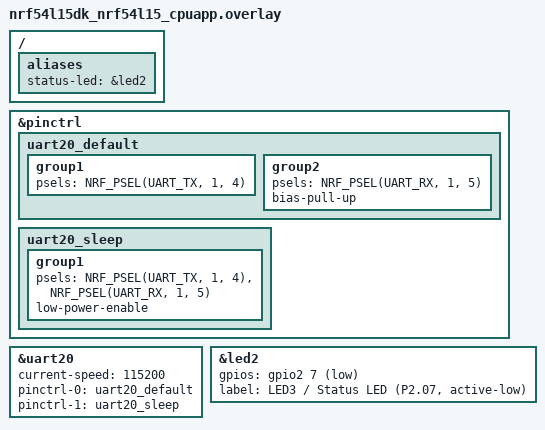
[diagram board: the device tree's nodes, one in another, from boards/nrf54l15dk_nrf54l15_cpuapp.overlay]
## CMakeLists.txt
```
#
# Copyright (c) 2018 Nordic Semiconductor
#
# SPDX-License-Identifier: LicenseRef-Nordic-5-Clause
#
cmake_minimum_required(VERSION 3.20.0)

find_package(Zephyr REQUIRED HINTS $ENV{ZEPHYR_BASE})
project(esb_ptx)

target_include_directories(app PRIVATE ../common)

# Pairing addresses are owned by xbox_central; PTX is runtime-only.
target_compile_definitions(app PRIVATE
  ESB_RADIO_SUBTREE=\"esb_ptx\"
  ESB_RADIO_MODE=ESB_MODE_PTX
  RC_ESB_RADIO_PERSIST=0
)

target_sources(app PRIVATE
  src/main.c
  src/rc_ptx_uart_channels.c
  src/rc_ptx_status_led.c
  src/rc_uart_bridge.c
  ../common/rc_link.c
  ../common/rc_channel_bank.c
  ../common/uart_rc_link.c
  ../common/rc_esb_radio.c
  ../common/rc_uart_esb_req_work.c
  ../common/rc_uart_log_fwd.c
)
```

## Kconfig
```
#
# Copyright (c) 2020 Nordic Semiconductor
#
# SPDX-License-Identifier: LicenseRef-Nordic-5-Clause
#

source "Kconfig.zephyr"

menu "Enhanced ShockBurst: Transmitter"

config ESB_PTX_APP_LOG_LEVEL
	int "Log level for the ESB PTX sample"
	default 2

endmenu
```

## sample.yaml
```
sample:
  name: ESB ptx
tests:
  sample.esb.ptx.build:
    sysbuild: true
    build_only: true
    integration_platforms:
      - nrf54l15dk/nrf54l15/cpuapp
    platform_allow:
      - nrf54l15dk/nrf54l15/cpuapp
    tags:
      - esb
      - ci_build
      - sysbuild
```

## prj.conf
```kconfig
#
# Copyright (c) 2019 Nordic Semiconductor ASA
#
# SPDX-License-Identifier: LicenseRef-Nordic-5-Clause
#
CONFIG_NCS_SAMPLES_DEFAULTS=y
CONFIG_ESB=y
CONFIG_DK_LIBRARY=y
CONFIG_CLOCK_CONTROL=y

# Required for ESB on nRF54L15 (DPPIC instance 10).
CONFIG_NRFX_DPPI10=y

# Console UART is shared with the Hub RC link (HUART-RC protocol).
CONFIG_UART_INTERRUPT_DRIVEN=y
CONFIG_SETTINGS=y
CONFIG_ZMS=y
CONFIG_SETTINGS_ZMS=y
CONFIG_PM_PARTITION_SIZE_SETTINGS_STORAGE=0x2000
CONFIG_FLASH=y
CONFIG_FLASH_MAP=y
CONFIG_ENTROPY_GENERATOR=y
CONFIG_GPIO=y

# Required by rc_uart_log_fwd custom log backend.
CONFIG_LOG_MODE_DEFERRED=y
CONFIG_LOG_OUTPUT=y

# Quiet default: WRN+ only. UART20 is shared with Hub HUART-RC link.
CONFIG_ESB_PTX_APP_LOG_LEVEL=2
CONFIG_LOG_DEFAULT_LEVEL=2
```

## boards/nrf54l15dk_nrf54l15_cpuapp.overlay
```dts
/*
 * SPDX-License-Identifier: LicenseRef-Nordic-5-Clause
 *
 * Console / Hub RC link on uart20: TX/RX only (no hardware flow control).
 * Match Ground BLE Hub uart30 speed for the wired RC link.
 *
 * Status LED on P2.07 (DK LED3 / led2): lost 1 Hz, PRX link solid, pair rapid.
 */

#include <zephyr/dt-bindings/gpio/gpio.h>

&pinctrl {
	uart20_default: uart20_default {
		group1 {
			psels = <NRF_PSEL(UART_TX, 1, 4)>;
		};

		group2 {
			psels = <NRF_PSEL(UART_RX, 1, 5)>;
			bias-pull-up;
		};
	};

	uart20_sleep: uart20_sleep {
		group1 {
			psels = <NRF_PSEL(UART_TX, 1, 4)>,
				<NRF_PSEL(UART_RX, 1, 5)>;
			low-power-enable;
		};
	};
};

&uart20 {
	current-speed = <115200>;
	pinctrl-0 = <&uart20_default>;
	pinctrl-1 = <&uart20_sleep>;
	pinctrl-names = "default", "sleep";
};

/*
 * Override DK LED3 (DT: led2, P2.07): external status LED is active-low.
 */
&led2 {
	gpios = <&gpio2 7 GPIO_ACTIVE_LOW>;
	label = "LED3 / Status LED (P2.07, active-low)";
};

/ {
	aliases {
		status-led = &led2;
	};
};
```

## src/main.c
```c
/*
 * Copyright (c) 2018 Nordic Semiconductor ASA
 *
 * SPDX-License-Identifier: LicenseRef-Nordic-5-Clause
 */
#include <zephyr/drivers/clock_control.h>
#include <zephyr/drivers/clock_control/nrf_clock_control.h>
#include <zephyr/drivers/gpio.h>
#include <zephyr/irq.h>
#include <zephyr/logging/log.h>
#include <nrf.h>
#include <esb.h>
#include <zephyr/device.h>
#include <zephyr/devicetree.h>
#include <zephyr/kernel.h>
#include <zephyr/types.h>
#include <dk_buttons_and_leds.h>
#if defined(CONFIG_CLOCK_CONTROL_NRF2)
#include <hal/nrf_lrcconf.h>
#endif
#include <nrf_erratas.h>
#if NRF54L_ERRATA_20_PRESENT
#include <hal/nrf_power.h>
#endif /* NRF54L_ERRATA_20_PRESENT */
#if defined(NRF54LM20A_ENGA_XXAA)
#include <hal/nrf_clock.h>
#endif /* defined(NRF54LM20A_ENGA_XXAA) */

#include "rc_channel_bank.h"
#include "rc_esb_radio.h"
#include "rc_link.h"
#include "rc_ptx_status_led.h"
#include "rc_ptx_uart_channels.h"
#include "rc_uart_bridge.h"

LOG_MODULE_REGISTER(esb_ptx, CONFIG_ESB_PTX_APP_LOG_LEVEL);

#define TX_INTERVAL_MS 100
#define PAIR_TX_INTERVAL_MS 1000

static bool ready = true;
static uint8_t ctrl_seq;
static uint8_t pair_seq;
static uint8_t peer_status_channels;
static struct esb_payload rx_payload;
static struct esb_payload tx_payload;
static struct rc_link_frame ctrl_frame;
static int64_t next_pair_tx_ms;
static bool pending_pair_restore;
static bool pair_probe_pending;
static bool pair_led_latched;
static struct uart_rc_esb_config saved_paired_cfg;

static void pair_complete(const char *reason)
{
	pending_pair_restore = false;
	pair_probe_pending = false;
	(void)rc_esb_radio_apply_cfg(&saved_paired_cfg);
	rc_esb_radio_end_pair_broadcast();
	if (pair_led_latched) {
		pair_led_latched = false;
		rc_ptx_status_led_set_pairing(false);
	}
	LOG_WRN("%s — enter UART CTRL forward", reason);
}

static void restore_paired_radio_cfg(void)
{
	if (!pending_pair_restore) {
		return;
	}

	(void)rc_esb_radio_apply_cfg(&saved_paired_cfg);
	pending_pair_restore = false;
}

static void handle_status_frame(const struct esb_payload *payload)
{
	struct rc_link_frame status;
	int err;

	err = rc_link_unpack(payload->data, payload->length, &status);
	if (err || status.type != RC_LINK_TYPE_STATUS) {
		LOG_DBG("Ignore invalid status frame: %d", err);
		return;
	}

	if (peer_status_channels != status.channel_count) {
		peer_status_channels = status.channel_count;
		LOG_DBG("Aircraft status channel count: %u", peer_status_channels);
	}

	rc_uart_bridge_on_esb_status(&status);
}

void event_handler(struct esb_evt const *event)
{
	static uint16_t pair_tx_ok;
	static uint16_t pair_tx_fail;

	ready = true;

	switch (event->evt_id) {
	case ESB_EVENT_TX_SUCCESS:
		if (rc_esb_radio_pair_broadcast_active()) {
			if (pending_pair_restore) {
				/* ACK on default listen address. */
				pair_tx_ok++;
				restore_paired_radio_cfg();
				pair_complete("PRX ACK on PAIR");
				LOG_WRN("pair stats ok=%u fail=%u", pair_tx_ok, pair_tx_fail);
				pair_tx_ok = 0;
				pair_tx_fail = 0;
			} else if (pair_probe_pending) {
				/*
				 * ACK on the new paired address — PRX already
				 * applied even if the default-addr ACK was lost.
				 */
				pair_probe_pending = false;
				pair_complete("PRX reachable on new addr");
				pair_tx_ok = 0;
				pair_tx_fail = 0;
			} else {
				restore_paired_radio_cfg();
			}
		} else {
			restore_paired_radio_cfg();
			/* PRX ACKed CTRL — RF link alive. */
			rc_ptx_status_led_on_link();
			LOG_DBG("Control frame sent");
		}
		break;
	case ESB_EVENT_TX_FAILED:
		if (pending_pair_restore && rc_esb_radio_pair_broadcast_active()) {
			pair_tx_fail++;
			LOG_WRN("PAIR TX no ACK (fail=%u) — probe new addr next",
				pair_tx_fail);
			restore_paired_radio_cfg();
			/* PRX may already have paired; probe on new addresses. */
			pair_probe_pending = true;
			pending_pair_restore = false;
		} else if (pair_probe_pending && rc_esb_radio_pair_broadcast_active()) {
			LOG_WRN("New-addr probe no ACK — resume PAIR broadcast");
			pair_probe_pending = false;
		} else {
			restore_paired_radio_cfg();
			LOG_DBG("Control/PAIR frame failed");
		}
		break;
	case ESB_EVENT_RX_RECEIVED:
		while (esb_read_rx_payload(&rx_payload) == 0) {
			handle_status_frame(&rx_payload);
		}
		/*
		 * STATUS on the new address during pair window also proves PRX
		 * applied the paired config.
		 */
		if (rc_esb_radio_pair_broadcast_active() && !pending_pair_restore) {
			pair_probe_pending = false;
			pair_complete("STATUS RX on new addr");
		}
		break;
	default:
		break;
	}
}

#if defined(CONFIG_CLOCK_CONTROL_NRF)
int clocks_start(void)
{
	int err;
	int res;
	struct onoff_manager *clk_mgr;
	struct onoff_client clk_cli;

	clk_mgr = z_nrf_clock_control_get_onoff(CLOCK_CONTROL_NRF_SUBSYS_HF);
	if (!clk_mgr) {
		LOG_ERR("Unable to get the Clock manager");
		return -ENXIO;
	}

	sys_notify_init_spinwait(&clk_cli.notify);

	err = onoff_request(clk_mgr, &clk_cli);
	if (err < 0) {
		LOG_ERR("Clock request failed: %d", err);
		return err;
	}

	do {
		err = sys_notify_fetch_result(&clk_cli.notify, &res);
		if (!err && res) {
			LOG_ERR("Clock could not be started: %d", res);
			return res;
		}
	} while (err);

#if NRF54L_ERRATA_20_PRESENT
	if (nrf54l_errata_20()) {
		nrf_power_task_trigger(NRF_POWER, NRF_POWER_TASK_CONSTLAT);
	}
#endif /* NRF54L_ERRATA_20_PRESENT */

#if defined(NRF54LM20A_ENGA_XXAA)
	nrf_clock_task_trigger(NRF_CLOCK, NRF_CLOCK_TASK_PLLSTART);
#endif

	LOG_DBG("HF clock started");
	return 0;
}

#elif defined(CONFIG_CLOCK_CONTROL_NRF2)

int clocks_start(void)
{
	int err;
	int res;
	const struct device *radio_clk_dev =
		DEVICE_DT_GET_OR_NULL(DT_CLOCKS_CTLR(DT_NODELABEL(radio)));
	struct onoff_client radio_cli;

	nrf_lrcconf_poweron_force_set(NRF_LRCCONF010, NRF_LRCCONF_POWER_DOMAIN_1, true);

	sys_notify_init_spinwait(&radio_cli.notify);

	err = nrf_clock_control_request(radio_clk_dev, NULL, &radio_cli);

	do {
		err = sys_notify_fetch_result(&radio_cli.notify, &res);
		if (!err && res) {
			LOG_ERR("Clock could not be started: %d", res);
			return res;
		}
	} while (err == -EAGAIN);

	nrf_lrcconf_clock_always_run_force_set(NRF_LRCCONF000, 0, true);
	nrf_lrcconf_task_trigger(NRF_LRCCONF000, NRF_LRCCONF_TASK_CLKSTART_0);

	LOG_DBG("HF clock started");
	return 0;
}

#else
BUILD_ASSERT(false, "No Clock Control driver");
#endif /* defined(CONFIG_CLOCK_CONTROL_NRF2) */

int esb_initialize(void)
{
	return rc_esb_radio_init(event_handler);
}

static int pack_ctrl_payload(struct esb_payload *payload)
{
	int len;

	len = rc_link_pack(&ctrl_frame, payload->data, sizeof(payload->data));
	if (len < 0) {
		return len;
	}

	payload->length = (uint8_t)len;
	payload->pipe = RC_LINK_PIPE;
	payload->noack = false;

	return 0;
}

static int pack_pair_payload(struct esb_payload *payload)
{
	struct rc_link_pair_payload pair_payload;
	struct rc_link_frame pair_frame;
	int err;
	int len;

	err = rc_esb_radio_export_pair_payload(&pair_payload);
	if (err != 0) {
		return err;
	}

	err = rc_link_pair_encode(&pair_payload, pair_seq++, &pair_frame);
	if (err != 0) {
		return err;
	}

	len = rc_link_pack(&pair_frame, payload->data, sizeof(payload->data));
	if (len < 0) {
		return len;
	}

	payload->length = (uint8_t)len;
	payload->pipe = RC_LINK_PIPE;
	payload->noack = false;

	return 0;
}

int main(void)
{
	int err;

	LOG_WRN("ESB PTX ready (UART RC; Hub owns pair store; Btn1 PAIR until PRX ACK)");

	err = clocks_start();
	if (err) {
		return 0;
	}

	err = dk_leds_init();
	if (err) {
		LOG_ERR("LEDs initialization failed, err %d", err);
		return 0;
	}

	err = rc_ptx_status_led_init();
	if (err) {
		LOG_WRN("status LED init failed: %d", err);
	}

	err = esb_initialize();
	if (err) {
		LOG_ERR("ESB initialization failed, err %d", err);
		return 0;
	}

	LOG_WRN("No local pair store — wait Hub SET_ADDR/APPLY (boot) or Btn1 PAIR");

	err = rc_uart_bridge_init();
	if (err) {
		LOG_ERR("UART RC bridge init failed, err %d", err);
		return 0;
	}

	next_pair_tx_ms = 0;

	while (1) {
		if (ready) {
			ready = false;
			esb_flush_tx();

			struct uart_rc_esb_config paired_cfg;
			const bool pair_window = rc_esb_radio_pair_broadcast_active();

			if (pair_window && !pair_led_latched) {
				pair_led_latched = true;
				rc_ptx_status_led_set_pairing(true);
			} else if (!pair_window && pair_led_latched) {
				pair_led_latched = false;
				rc_ptx_status_led_set_pairing(false);
			}

			if (pair_window && pair_probe_pending) {
				/*
				 * After a lost default-addr ACK, PRX may already be on
				 * the new addresses. Probe there before more PAIR TX.
				 */
				(void)rc_esb_radio_get_config(&paired_cfg);
				saved_paired_cfg = paired_cfg;
				err = pack_pair_payload(&tx_payload);
				if (err) {
					LOG_ERR("Pack probe frame failed: %d", err);
					pair_probe_pending = false;
					ready = true;
					continue;
				}
				pending_pair_restore = false;
				LOG_WRN("Probe TX on new paired addr (len=%u)", tx_payload.length);
			} else if (pair_window && k_uptime_get() >= next_pair_tx_ms) {
				next_pair_tx_ms = k_uptime_get() + PAIR_TX_INTERVAL_MS;

				(void)rc_esb_radio_get_config(&paired_cfg);
				err = pack_pair_payload(&tx_payload);
				if (err) {
					LOG_ERR("Pack pair frame failed: %d", err);
					ready = true;
					continue;
				}

				err = rc_esb_radio_apply_pair_listen();
				if (err != 0) {
					LOG_ERR("Apply pair listen failed: %d", err);
					ready = true;
					continue;
				}
				saved_paired_cfg = paired_cfg;
				pending_pair_restore = true;
				pair_probe_pending = false;
				LOG_WRN("PAIR TX on default addr (seq payload len=%u)",
					tx_payload.length);
			} else if (!pair_window) {
				const struct rc_channel_bank *bank =
					rc_ptx_get_active_control_bank();

				if (bank == NULL) {
					ready = true;
					continue;
				}

				err = rc_link_frame_fill(&ctrl_frame, RC_LINK_TYPE_CTRL, ctrl_seq++, 0,
							 bank);
				if (err) {
					LOG_ERR("Prepare control frame failed: %d", err);
					ready = true;
					continue;
				}

				err = pack_ctrl_payload(&tx_payload);
			} else {
				/* Pair window active but waiting for next PAIR slot. */
				ready = true;
				continue;
			}
			if (err) {
				LOG_ERR("Pack TX frame failed: %d", err);
				ready = true;
				continue;
			}

			err = esb_write_payload(&tx_payload);
			if (err) {
				LOG_ERR("Payload write failed, err %d", err);
				restore_paired_radio_cfg();
				ready = true;
			}
		}
		k_sleep(K_MSEC(TX_INTERVAL_MS));
	}
}
```

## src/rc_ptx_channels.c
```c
/*
 * Copyright (c) 2026
 *
 * SPDX-License-Identifier: LicenseRef-Nordic-5-Clause
 */

#include "rc_ptx_channels.h"

#include <zephyr/sys/util.h>

static uint8_t *ctrl_seq_ref;

struct ptx_base_ctx {
	uint16_t base;
};

static int read_scaled_base(void *ctx, uint16_t *value)
{
	const struct ptx_base_ctx *cfg = ctx;

	*value = (uint16_t)(cfg->base + (ctrl_seq_ref ? (*ctrl_seq_ref % 100U) : 0U));
	return 0;
}

static int read_fixed(void *ctx, uint16_t *value)
{
	*value = (uint16_t)(uintptr_t)ctx;
	return 0;
}

static struct ptx_base_ctx aileron_cfg = {
	.base = 1500,
};

static const struct rc_channel_slot ptx_slots[] = {
	{ read_fixed, NULL, (void *)(uintptr_t)1000 },
	{ read_scaled_base, NULL, &aileron_cfg },
	{ read_fixed, NULL, (void *)(uintptr_t)1500 },
	{ read_fixed, NULL, (void *)(uintptr_t)1500 },
	{ read_fixed, NULL, (void *)(uintptr_t)1800 },
	{ read_fixed, NULL, (void *)(uintptr_t)1200 },
};

const struct rc_channel_bank rc_ptx_control_bank = {
	.slots = ptx_slots,
	.slot_count = ARRAY_SIZE(ptx_slots),
};

void rc_ptx_channels_bind_seq(uint8_t *seq)
{
	ctrl_seq_ref = seq;
}
```

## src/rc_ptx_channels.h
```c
/*
 * Copyright (c) 2026
 *
 * SPDX-License-Identifier: LicenseRef-Nordic-5-Clause
 */

#ifndef RC_PTX_CHANNELS_H_
#define RC_PTX_CHANNELS_H_

#include <stdint.h>

#include "rc_channel_bank.h"

extern const struct rc_channel_bank rc_ptx_control_bank;

void rc_ptx_channels_bind_seq(uint8_t *seq);

#endif /* RC_PTX_CHANNELS_H_ */
```

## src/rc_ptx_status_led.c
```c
/*
 * SPDX-License-Identifier: LicenseRef-Nordic-5-Clause
 */

#include "rc_ptx_status_led.h"

#include <errno.h>

#include <zephyr/device.h>
#include <zephyr/devicetree.h>
#include <zephyr/drivers/gpio.h>
#include <zephyr/kernel.h>
#include <zephyr/logging/log.h>

LOG_MODULE_REGISTER(rc_ptx_status_led, CONFIG_ESB_PTX_APP_LOG_LEVEL);

#if DT_NODE_EXISTS(DT_ALIAS(status_led))
#define STATUS_LED_NODE DT_ALIAS(status_led)
static const struct gpio_dt_spec status_led = GPIO_DT_SPEC_GET(STATUS_LED_NODE, gpios);
#define STATUS_LED_AVAILABLE 1
#else
#define STATUS_LED_AVAILABLE 0
#endif

/* 500 ms on / 500 ms off → 1 Hz when link lost. */
#define LOST_PERIOD_MS       1000U
#define PAIRING_PERIOD_MS     160U /* 80 ms on / 80 ms off */
/*
 * After the last CTRL TX_SUCCESS (PRX ACK), wait this long then 1 Hz lost blink.
 * Must be > Hub CTRL / PTX TX interval (~100 ms).
 */
#define LINK_LOST_TIMEOUT_MS  500U

enum status_led_mode {
	STATUS_LED_LOST = 0, /* 1 Hz */
	STATUS_LED_LINK,     /* solid */
	STATUS_LED_PAIRING,  /* rapid */
};

static enum status_led_mode mode = STATUS_LED_LOST;
static bool led_on;
static bool pairing_active;
static struct k_work_delayable blink_work;
static struct k_work_delayable lost_work;

static uint32_t period_for_mode(enum status_led_mode m)
{
	switch (m) {
	case STATUS_LED_PAIRING:
		return PAIRING_PERIOD_MS;
	case STATUS_LED_LOST:
		return LOST_PERIOD_MS;
	case STATUS_LED_LINK:
	default:
		return 0U;
	}
}

static void led_apply(bool on)
{
#if STATUS_LED_AVAILABLE
	(void)gpio_pin_set_dt(&status_led, on ? 1 : 0);
#else
	ARG_UNUSED(on);
#endif
	led_on = on;
}

static void apply_mode(enum status_led_mode next)
{
	uint32_t period;

	mode = next;
	(void)k_work_cancel_delayable(&blink_work);

	period = period_for_mode(mode);
	if (period == 0U) {
		/* LINK: solid on. */
		led_apply(true);
		return;
	}

	led_apply(true);
	(void)k_work_reschedule(&blink_work, K_MSEC(period / 2U));
}

static void blink_work_handler(struct k_work *work)
{
	uint32_t period;

	ARG_UNUSED(work);

	period = period_for_mode(mode);
	if (period == 0U) {
		led_apply(true);
		return;
	}

	led_apply(!led_on);
	(void)k_work_reschedule(&blink_work, K_MSEC(period / 2U));
}

static void lost_work_handler(struct k_work *work)
{
	ARG_UNUSED(work);

	if (pairing_active) {
		return;
	}

	apply_mode(STATUS_LED_LOST);
}

int rc_ptx_status_led_init(void)
{
#if !STATUS_LED_AVAILABLE
	LOG_WRN("status-led alias missing — status LED disabled");
	return -ENOENT;
#else
	int err;

	if (!gpio_is_ready_dt(&status_led)) {
		LOG_ERR("status-led GPIO not ready");
		return -ENODEV;
	}

	err = gpio_pin_configure_dt(&status_led, GPIO_OUTPUT_INACTIVE);
	if (err) {
		LOG_ERR("status-led configure failed: %d", err);
		return err;
	}

	k_work_init_delayable(&blink_work, blink_work_handler);
	k_work_init_delayable(&lost_work, lost_work_handler);
	pairing_active = false;
	apply_mode(STATUS_LED_LOST);
	LOG_WRN("status LED P2.07 — lost 1 Hz / PRX link solid / pair rapid");
	return 0;
#endif
}

void rc_ptx_status_led_on_link(void)
{
#if !STATUS_LED_AVAILABLE
	return;
#else
	if (pairing_active) {
		return;
	}

	(void)k_work_reschedule(&lost_work, K_MSEC(LINK_LOST_TIMEOUT_MS));

	if (mode != STATUS_LED_LINK) {
		apply_mode(STATUS_LED_LINK);
	}
#endif
}

void rc_ptx_status_led_set_pairing(bool pairing)
{
#if !STATUS_LED_AVAILABLE
	ARG_UNUSED(pairing);
	return;
#else
	pairing_active = pairing;
	(void)k_work_cancel_delayable(&lost_work);

	if (pairing) {
		apply_mode(STATUS_LED_PAIRING);
		return;
	}

	apply_mode(STATUS_LED_LOST);
#endif
}
```

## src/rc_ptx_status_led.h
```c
/*
 * SPDX-License-Identifier: LicenseRef-Nordic-5-Clause
 *
 * Status LED on DT alias status-led (P2.07):
 *   lost     — 1 Hz blink (no ESB ACK from PRX)
 *   link     — solid on (CTRL TX ACKed by PRX)
 *   pairing  — rapid blink (OTA PAIR broadcast)
 */

#ifndef RC_PTX_STATUS_LED_H_
#define RC_PTX_STATUS_LED_H_

#include <stdbool.h>

int rc_ptx_status_led_init(void);

/** ISR-safe: PRX ACK'd CTRL — solid on; refresh lost timer. */
void rc_ptx_status_led_on_link(void);

/** OTA PAIR broadcast indication (highest priority over link/lost). */
void rc_ptx_status_led_set_pairing(bool pairing);

#endif /* RC_PTX_STATUS_LED_H_ */
```

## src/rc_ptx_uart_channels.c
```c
/*
 * Copyright (c) 2026
 *
 * SPDX-License-Identifier: LicenseRef-Nordic-5-Clause
 */

#include "rc_ptx_uart_channels.h"

#include <zephyr/kernel.h>
#include <zephyr/sys/util.h>

static uint16_t uart_channel_values[UART_RC_LINK_MAX_CHANNELS];
static size_t uart_channel_count;
static int64_t uart_last_update_ms;

static int read_uart_channel(void *ctx, uint16_t *value)
{
	uintptr_t index = (uintptr_t)ctx;

	if (index >= uart_channel_count) {
		return -ENOENT;
	}

	*value = uart_channel_values[index];
	return 0;
}

static bool uart_channel_slot_available(void *ctx)
{
	uintptr_t index = (uintptr_t)ctx;

	return rc_ptx_uart_channels_active() && index < uart_channel_count;
}

static struct rc_channel_slot uart_slots[UART_RC_LINK_MAX_CHANNELS];

static const struct rc_channel_bank uart_bank = {
	.slots = uart_slots,
	.slot_count = ARRAY_SIZE(uart_slots),
};

void rc_ptx_uart_channels_update(const struct uart_rc_link_ctrl *ctrl)
{
	if (ctrl == NULL || ctrl->channel_count == 0U ||
	    ctrl->channel_count > UART_RC_LINK_MAX_CHANNELS) {
		return;
	}

	uart_channel_count = ctrl->channel_count;

	for (uint8_t i = 0; i < ctrl->channel_count; i++) {
		uart_channel_values[i] = ctrl->channels[i];
	}

	uart_last_update_ms = k_uptime_get();
}

bool rc_ptx_uart_channels_active(void)
{
	if (uart_channel_count == 0U) {
		return false;
	}

	return (k_uptime_get() - uart_last_update_ms) < RC_PTX_UART_LINK_TIMEOUT_MS;
}

const struct rc_channel_bank *rc_ptx_get_active_control_bank(void)
{
	if (!rc_ptx_uart_channels_active()) {
		return NULL;
	}

	return &uart_bank;
}

static int rc_ptx_uart_channels_init(void)
{
	for (size_t i = 0; i < ARRAY_SIZE(uart_slots); i++) {
		uart_slots[i].read = read_uart_channel;
		uart_slots[i].is_available = uart_channel_slot_available;
		uart_slots[i].ctx = (void *)i;
	}

	return 0;
}

SYS_INIT(rc_ptx_uart_channels_init, APPLICATION, CONFIG_APPLICATION_INIT_PRIORITY);
```

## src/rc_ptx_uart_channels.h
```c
/*
 * Copyright (c) 2026
 *
 * SPDX-License-Identifier: LicenseRef-Nordic-5-Clause
 */

#ifndef RC_PTX_UART_CHANNELS_H_
#define RC_PTX_UART_CHANNELS_H_

#include <stdint.h>

#include "rc_channel_bank.h"
#include "uart_rc_link.h"

#define RC_PTX_UART_LINK_TIMEOUT_MS 500

void rc_ptx_uart_channels_update(const struct uart_rc_link_ctrl *ctrl);
bool rc_ptx_uart_channels_active(void);

/** Returns UART channel bank, or NULL when Hub link is idle / timed out. */
const struct rc_channel_bank *rc_ptx_get_active_control_bank(void);

#endif /* RC_PTX_UART_CHANNELS_H_ */
```

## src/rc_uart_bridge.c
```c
/*
 * Copyright (c) 2026
 *
 * SPDX-License-Identifier: LicenseRef-Nordic-5-Clause
 */

#include "rc_uart_bridge.h"

#include <zephyr/devicetree.h>
#include <zephyr/logging/log.h>

#include "rc_esb_radio.h"
#include "rc_ptx_uart_channels.h"
#include "rc_uart_esb_req_work.h"
#include "rc_uart_log_fwd.h"
#include "uart_rc_link.h"

LOG_MODULE_REGISTER(rc_uart_bridge, CONFIG_ESB_PTX_APP_LOG_LEVEL);

static struct uart_rc_link uart_link;
static uint8_t uart_status_seq;

static void on_uart_ctrl(const struct uart_rc_link_ctrl *ctrl, void *user_data)
{
	ARG_UNUSED(user_data);

	rc_ptx_uart_channels_update(ctrl);
	LOG_DBG("UART ctrl seq=%u count=%u", ctrl->seq, ctrl->channel_count);
}

static void on_uart_esb_req(const struct uart_rc_esb_req *req, void *user_data)
{
	ARG_UNUSED(user_data);

	(void)rc_uart_esb_req_submit(&uart_link, req);
}

static void on_uart_debug_ctrl(const struct uart_rc_debug_ctrl *ctrl, void *user_data)
{
	ARG_UNUSED(user_data);

	(void)rc_uart_log_fwd_apply(ctrl);
}

int rc_uart_bridge_init(void)
{
	const struct device *uart = DEVICE_DT_GET(DT_CHOSEN(zephyr_console));
	struct uart_rc_link_handlers handlers = {
		.on_ctrl = on_uart_ctrl,
		.on_status = NULL,
		.on_esb_req = on_uart_esb_req,
		.on_esb_rsp = NULL,
		.on_debug_ctrl = on_uart_debug_ctrl,
		.on_debug_log = NULL,
		.user_data = NULL,
	};
	int err;

	err = rc_uart_esb_req_work_init();
	if (err != 0) {
		return err;
	}

	err = uart_rc_link_init(&uart_link, uart, &handlers);
	if (err != 0) {
		return err;
	}

	err = rc_uart_log_fwd_init(&uart_link);
	if (err != 0) {
		return err;
	}

	err = uart_rc_link_start_rx(&uart_link);
	if (err != 0) {
		LOG_ERR("UART RC link RX failed: %d", err);
		return err;
	}

	LOG_DBG("UART RC link on console (HDLC 0x%02x, multiplexed with logs)",
		UART_RC_LINK_HDLC_FLAG);
	return 0;
}

struct uart_rc_link *rc_uart_bridge_link(void)
{
	return &uart_link;
}

void rc_uart_bridge_on_esb_status(const struct rc_link_frame *status)
{
	struct uart_rc_link_status uart_status;

	if (status == NULL || status->type != RC_LINK_TYPE_STATUS) {
		return;
	}

	uart_status.seq = uart_status_seq++;
	uart_status.roll = 0;
	uart_status.pitch = 0;
	uart_status.yaw = 0;
	uart_status.battery_mv = 0U;
	uart_status.flags = status->flags;

	if (status->channel_count > 0U) {
		uart_status.battery_mv = status->channels[0];
	}
	if (status->channel_count > 1U) {
		uart_status.roll = (int16_t)status->channels[1];
	}
	if (status->channel_count > 2U) {
		uart_status.pitch = (int16_t)status->channels[2];
	}

	(void)uart_rc_link_send_status(&uart_link, &uart_status);
}
```

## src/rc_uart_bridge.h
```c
/*
 * Copyright (c) 2026
 *
 * SPDX-License-Identifier: LicenseRef-Nordic-5-Clause
 */

#ifndef RC_UART_BRIDGE_H_
#define RC_UART_BRIDGE_H_

#include "rc_link.h"
#include "uart_rc_link.h"

int rc_uart_bridge_init(void);
struct uart_rc_link *rc_uart_bridge_link(void);
void rc_uart_bridge_on_esb_status(const struct rc_link_frame *status);

#endif /* RC_UART_BRIDGE_H_ */
```
